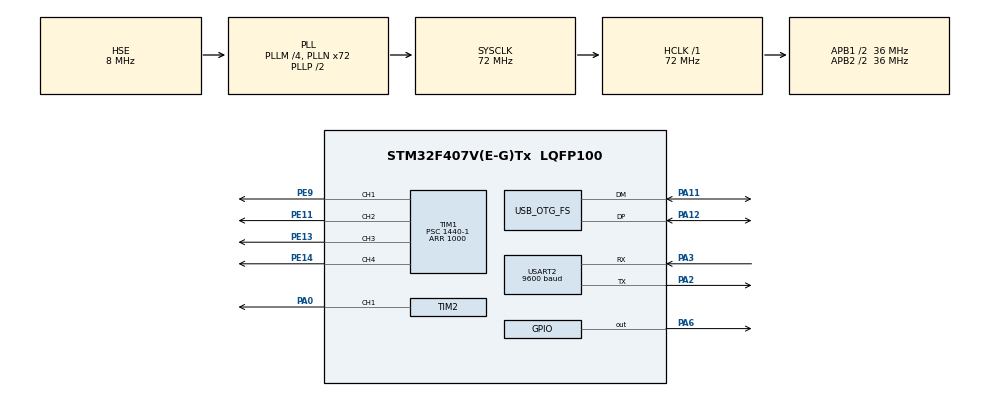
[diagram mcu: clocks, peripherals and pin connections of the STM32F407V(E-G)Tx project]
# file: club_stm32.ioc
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Mcu.Family=STM32F4
Mcu.Name=STM32F407V(E-G)Tx
Mcu.Package=LQFP100
NVIC.OTG_FS_IRQn=true\:0\:0\:false\:false\:true\:false\:true\:true
NVIC.PriorityGroup=NVIC_PRIORITYGROUP_4
NVIC.USART2_IRQn=true\:0\:0\:false\:false\:true\:true\:true\:true
PA0-WKUP.Signal=S_TIM2_CH1_ETR
PA11.Mode=Device_Only
PA11.Signal=USB_OTG_FS_DM
PA12.Mode=Device_Only
PA12.Signal=USB_OTG_FS_DP
PA2.Mode=Asynchronous
PA2.Signal=USART2_TX
PA3.Mode=Asynchronous
PA3.Signal=USART2_RX
PA6.Signal=GPIO_Output
PE11.Signal=S_TIM1_CH2
PE13.Signal=S_TIM1_CH3
PE14.Signal=S_TIM1_CH4
PE9.Signal=S_TIM1_CH1
PH0-OSC_IN.Mode=HSE-External-Oscillator
PH0-OSC_IN.Signal=RCC_OSC_IN
PH1-OSC_OUT.Mode=HSE-External-Oscillator
PH1-OSC_OUT.Signal=RCC_OSC_OUT
ProjectManager.HeapSize=0x200
ProjectManager.StackSize=0x400
ProjectManager.TargetToolchain=STM32CubeIDE
RCC.48MHZClocksFreq_Value=48000000
RCC.AHBFreq_Value=72000000
RCC.APB1CLKDivider=RCC_HCLK_DIV2
RCC.APB1Freq_Value=36000000
RCC.APB1TimFreq_Value=72000000
RCC.APB2CLKDivider=RCC_HCLK_DIV2
RCC.APB2Freq_Value=36000000
RCC.APB2TimFreq_Value=72000000
RCC.CortexFreq_Value=72000000
RCC.HCLKFreq_Value=72000000
RCC.HSE_VALUE=8000000
RCC.HSI_VALUE=16000000
RCC.LSE_VALUE=32768
RCC.PLLM=4
RCC.PLLN=72
RCC.PLLQ=3
RCC.SYSCLKFreq_VALUE=72000000
RCC.SYSCLKSource=RCC_SYSCLKSOURCE_PLLCLK
RCC.VCOOutputFreq_Value=144000000
SH.S_TIM1_CH1.0=TIM1_CH1,PWM Generation1 CH1
SH.S_TIM1_CH2.0=TIM1_CH2,PWM Generation2 CH2
SH.S_TIM1_CH3.0=TIM1_CH3,PWM Generation3 CH3
SH.S_TIM1_CH4.0=TIM1_CH4,PWM Generation4 CH4
SH.S_TIM2_CH1_ETR.0=TIM2_CH1,PWM Generation1 CH1
TIM1.Channel-PWM\ Generation1\ CH1=TIM_CHANNEL_1
TIM1.Channel-PWM\ Generation2\ CH2=TIM_CHANNEL_2
TIM1.Channel-PWM\ Generation3\ CH3=TIM_CHANNEL_3
TIM1.Channel-PWM\ Generation4\ CH4=TIM_CHANNEL_4
TIM1.Period=1000
TIM1.Prescaler=1440-1
TIM2.Channel-PWM\ Generation1\ CH1=TIM_CHANNEL_1
TIM2.Period=1000
TIM2.Prescaler=1440
USART2.BaudRate=9600
USART2.VirtualMode=VM_ASYNC
USB_DEVICE.CLASS_NAME_FS=CDC
USB_DEVICE.VirtualMode-CDC_FS=Cdc
USB_DEVICE.VirtualModeFS=Cdc_FS
USB_OTG_FS.VirtualMode=Device_Only
VP_TIM1_VS_ClockSourceINT.Mode=Internal
VP_TIM2_VS_ClockSourceINT.Mode=Internal
VP_USB_DEVICE_VS_USB_DEVICE_CDC_FS.Mode=CDC_FS
board=custom

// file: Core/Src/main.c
/* USER CODE BEGIN Header */
/**
  ******************************************************************************
  * @file           : main.c
  * @brief          : Main program body
  ******************************************************************************
  * @attention
  *
  * Copyright (c) 2024 STMicroelectronics.
  * All rights reserved.
  *
  * This software is licensed under terms that can be found in the LICENSE file
  * in the root directory of this software component.
  * If no LICENSE file comes with this software, it is provided AS-IS.
  *
  ******************************************************************************
  */
/* USER CODE END Header */
#include "main.h"
#include "usb_device.h"
#include "usbd_cdc_if.h"
#include <stdio.h>
#include <stdint.h>
#include <stdlib.h>

/* USER CODE BEGIN Includes */
#define RX_BUFFER_SIZE 5
uint8_t rxBuffer[RX_BUFFER_SIZE];
uint8_t rxIndex = 0;
/* USER CODE END Includes */

TIM_HandleTypeDef htim1;
TIM_HandleTypeDef htim2;

UART_HandleTypeDef huart2;

void SystemClock_Config(void);
static void MX_GPIO_Init(void);
static void MX_TIM1_Init(void);
static void MX_USART2_UART_Init(void);
static void MX_TIM2_Init(void);

int main(void)
{

  /* MCU Configuration--------------------------------------------------------*/

  /* Reset of all peripherals, Initializes the Flash interface and the Systick. */
  HAL_Init();

  /* Configure the system clock */
  SystemClock_Config();

  /* Initialize all configured peripherals */
  MX_GPIO_Init();
  MX_TIM1_Init();
  MX_TIM2_Init();
  MX_USB_DEVICE_Init();
  MX_USART2_UART_Init();
  HAL_TIM_PWM_Start(&htim1, TIM_CHANNEL_1);
  HAL_TIM_PWM_Start(&htim1, TIM_CHANNEL_2);
  HAL_TIM_PWM_Start(&htim1, TIM_CHANNEL_3);
  HAL_TIM_PWM_Start(&htim1, TIM_CHANNEL_4);
  HAL_TIM_PWM_Start(&htim2, TIM_CHANNEL_1);
  HAL_UART_Receive_IT(&huart2, &rxBuffer[rxIndex], 1);
  /* USER CODE BEGIN 2 */
//  HAL_UART_Receive_IT(&huart1, &rxBuffer[rxIndex], 1);

  /* USER CODE END 2 */

  /* Infinite loop */
    while (1)
    {

    }
}

void SystemClock_Config(void)
{
  RCC_OscInitTypeDef RCC_OscInitStruct = {0};
  RCC_ClkInitTypeDef RCC_ClkInitStruct = {0};

  /** Configure the main internal regulator output voltage
  */
  __HAL_RCC_PWR_CLK_ENABLE();
  __HAL_PWR_VOLTAGESCALING_CONFIG(PWR_REGULATOR_VOLTAGE_SCALE1);

  /** Initializes the RCC Oscillators according to the specified parameters
  * in the RCC_OscInitTypeDef structure.
  */
  RCC_OscInitStruct.OscillatorType = RCC_OSCILLATORTYPE_HSE;
  RCC_OscInitStruct.HSEState = RCC_HSE_ON;
  RCC_OscInitStruct.PLL.PLLState = RCC_PLL_ON;
  RCC_OscInitStruct.PLL.PLLSource = RCC_PLLSOURCE_HSE;
  RCC_OscInitStruct.PLL.PLLM = 4;
  RCC_OscInitStruct.PLL.PLLN = 72;
  RCC_OscInitStruct.PLL.PLLP = RCC_PLLP_DIV2;
  RCC_OscInitStruct.PLL.PLLQ = 3;
  if (HAL_RCC_OscConfig(&RCC_OscInitStruct) != HAL_OK)
  {
    Error_Handler();
  }

  /** Initializes the CPU, AHB and APB buses clocks
  */
  RCC_ClkInitStruct.ClockType = RCC_CLOCKTYPE_HCLK|RCC_CLOCKTYPE_SYSCLK
                              |RCC_CLOCKTYPE_PCLK1|RCC_CLOCKTYPE_PCLK2;
  RCC_ClkInitStruct.SYSCLKSource = RCC_SYSCLKSOURCE_PLLCLK;
  RCC_ClkInitStruct.AHBCLKDivider = RCC_SYSCLK_DIV1;
  RCC_ClkInitStruct.APB1CLKDivider = RCC_HCLK_DIV2;
  RCC_ClkInitStruct.APB2CLKDivider = RCC_HCLK_DIV2;

  if (HAL_RCC_ClockConfig(&RCC_ClkInitStruct, FLASH_LATENCY_2) != HAL_OK)
  {
    Error_Handler();
  }
}

static void MX_TIM1_Init(void)
{

  TIM_ClockConfigTypeDef sClockSourceConfig = {0};
  TIM_MasterConfigTypeDef sMasterConfig = {0};
  TIM_OC_InitTypeDef sConfigOC = {0};
  TIM_BreakDeadTimeConfigTypeDef sBreakDeadTimeConfig = {0};

  htim1.Instance = TIM1;
  htim1.Init.Prescaler = 1440-1;
  htim1.Init.CounterMode = TIM_COUNTERMODE_UP;
  htim1.Init.Period = 1000;
  htim1.Init.ClockDivision = TIM_CLOCKDIVISION_DIV1;
  htim1.Init.RepetitionCounter = 0;
  htim1.Init.AutoReloadPreload = TIM_AUTORELOAD_PRELOAD_DISABLE;
  if (HAL_TIM_Base_Init(&htim1) != HAL_OK)
  {
    Error_Handler();
  }
  sClockSourceConfig.ClockSource = TIM_CLOCKSOURCE_INTERNAL;
  if (HAL_TIM_ConfigClockSource(&htim1, &sClockSourceConfig) != HAL_OK)
  {
    Error_Handler();
  }
  if (HAL_TIM_PWM_Init(&htim1) != HAL_OK)
  {
    Error_Handler();
  }
  sMasterConfig.MasterOutputTrigger = TIM_TRGO_RESET;
  sMasterConfig.MasterSlaveMode = TIM_MASTERSLAVEMODE_DISABLE;
  if (HAL_TIMEx_MasterConfigSynchronization(&htim1, &sMasterConfig) != HAL_OK)
  {
    Error_Handler();
  }
  sConfigOC.OCMode = TIM_OCMODE_PWM1;
  sConfigOC.Pulse = 0;
  sConfigOC.OCPolarity = TIM_OCPOLARITY_HIGH;
  sConfigOC.OCNPolarity = TIM_OCNPOLARITY_HIGH;
  sConfigOC.OCFastMode = TIM_OCFAST_DISABLE;
  sConfigOC.OCIdleState = TIM_OCIDLESTATE_RESET;
  sConfigOC.OCNIdleState = TIM_OCNIDLESTATE_RESET;
  if (HAL_TIM_PWM_ConfigChannel(&htim1, &sConfigOC, TIM_CHANNEL_1) != HAL_OK)
  {
    Error_Handler();
  }
  if (HAL_TIM_PWM_ConfigChannel(&htim1, &sConfigOC, TIM_CHANNEL_2) != HAL_OK)
  {
    Error_Handler();
  }
  if (HAL_TIM_PWM_ConfigChannel(&htim1, &sConfigOC, TIM_CHANNEL_3) != HAL_OK)
  {
    Error_Handler();
  }
  if (HAL_TIM_PWM_ConfigChannel(&htim1, &sConfigOC, TIM_CHANNEL_4) != HAL_OK)
  {
    Error_Handler();
  }
  sBreakDeadTimeConfig.OffStateRunMode = TIM_OSSR_DISABLE;
  sBreakDeadTimeConfig.OffStateIDLEMode = TIM_OSSI_DISABLE;
  sBreakDeadTimeConfig.LockLevel = TIM_LOCKLEVEL_OFF;
  sBreakDeadTimeConfig.DeadTime = 0;
  sBreakDeadTimeConfig.BreakState = TIM_BREAK_DISABLE;
  sBreakDeadTimeConfig.BreakPolarity = TIM_BREAKPOLARITY_HIGH;
  sBreakDeadTimeConfig.AutomaticOutput = TIM_AUTOMATICOUTPUT_DISABLE;
  if (HAL_TIMEx_ConfigBreakDeadTime(&htim1, &sBreakDeadTimeConfig) != HAL_OK)
  {
    Error_Handler();
  }
  HAL_TIM_MspPostInit(&htim1);

}

static void MX_TIM2_Init(void)
{

  TIM_ClockConfigTypeDef sClockSourceConfig = {0};
  TIM_MasterConfigTypeDef sMasterConfig = {0};
  TIM_OC_InitTypeDef sConfigOC = {0};

  htim2.Instance = TIM2;
  htim2.Init.Prescaler = 1440;
  htim2.Init.CounterMode = TIM_COUNTERMODE_UP;
  htim2.Init.Period = 1000;
  htim2.Init.ClockDivision = TIM_CLOCKDIVISION_DIV1;
  htim2.Init.AutoReloadPreload = TIM_AUTORELOAD_PRELOAD_DISABLE;
  if (HAL_TIM_Base_Init(&htim2) != HAL_OK)
  {
    Error_Handler();
  }
  sClockSourceConfig.ClockSource = TIM_CLOCKSOURCE_INTERNAL;
  if (HAL_TIM_ConfigClockSource(&htim2, &sClockSourceConfig) != HAL_OK)
  {
    Error_Handler();
  }
  if (HAL_TIM_PWM_Init(&htim2) != HAL_OK)
  {
    Error_Handler();
  }
  sMasterConfig.MasterOutputTrigger = TIM_TRGO_RESET;
  sMasterConfig.MasterSlaveMode = TIM_MASTERSLAVEMODE_DISABLE;
  if (HAL_TIMEx_MasterConfigSynchronization(&htim2, &sMasterConfig) != HAL_OK)
  {
    Error_Handler();
  }
  sConfigOC.OCMode = TIM_OCMODE_PWM1;
  sConfigOC.Pulse = 0;
  sConfigOC.OCPolarity = TIM_OCPOLARITY_HIGH;
  sConfigOC.OCFastMode = TIM_OCFAST_DISABLE;
  if (HAL_TIM_PWM_ConfigChannel(&htim2, &sConfigOC, TIM_CHANNEL_1) != HAL_OK)
  {
    Error_Handler();
  }
  HAL_TIM_MspPostInit(&htim2);

}

static void MX_USART2_UART_Init(void)
{

  huart2.Instance = USART2;
  huart2.Init.BaudRate = 9600;
  huart2.Init.WordLength = UART_WORDLENGTH_8B;
  huart2.Init.StopBits = UART_STOPBITS_1;
  huart2.Init.Parity = UART_PARITY_NONE;
  huart2.Init.Mode = UART_MODE_TX_RX;
  huart2.Init.HwFlowCtl = UART_HWCONTROL_NONE;
  huart2.Init.OverSampling = UART_OVERSAMPLING_16;
  if (HAL_UART_Init(&huart2) != HAL_OK)
  {
    Error_Handler();
  }

}

static void MX_GPIO_Init(void)
{
  GPIO_InitTypeDef GPIO_InitStruct = {0};

  /* GPIO Ports Clock Enable */
  __HAL_RCC_GPIOH_CLK_ENABLE();
  __HAL_RCC_GPIOA_CLK_ENABLE();
  __HAL_RCC_GPIOE_CLK_ENABLE();

  /*Configure GPIO pin Output Level */
  HAL_GPIO_WritePin(GPIOA, GPIO_PIN_6, GPIO_PIN_RESET);

  /*Configure GPIO pin : PA6 */
  GPIO_InitStruct.Pin = GPIO_PIN_6;
  GPIO_InitStruct.Mode = GPIO_MODE_OUTPUT_PP;
  GPIO_InitStruct.Pull = GPIO_NOPULL;
  GPIO_InitStruct.Speed = GPIO_SPEED_FREQ_LOW;
  HAL_GPIO_Init(GPIOA, &GPIO_InitStruct);

}

void Error_Handler(void)
{
  __disable_irq();
  while (1)
  {
  }
}

int get_angle(uint8_t *rxBuffer) {
    // Check if rxBuffer is valid
    if (rxBuffer == NULL) {
        printf("Invalid input\n");
        return -1;
    }

    // Check if the starting characters are "s6"
    if (rxBuffer[0] == 's') {
        printf("The input starts with 's6'.\n");
    } else {
        printf("The input does not start with 's6'.\n");
        return -1;  // Return an error or handle as needed
    }

    // Create a temporary string buffer to hold the last 3 characters as a string
    char angleStr[4] = {0};  // 3 characters for angle + 1 null terminator
    angleStr[0] = rxBuffer[2];
    angleStr[1] = rxBuffer[3];
    angleStr[2] = rxBuffer[4];

    // Convert the extracted characters to an integer
    int angle = atoi(angleStr);

    return angle;
}

void HAL_UART_RxCpltCallback(UART_HandleTypeDef *huart)
{
    if (huart->Instance == USART2)
    {
        // Increment the index for each received byte
        rxIndex++;

        // Check if we've received the full 5-byte message
        if (rxIndex >= RX_BUFFER_SIZE)
        {
            // Process the full message without echoing it back to the PC
            if (rxBuffer[0] == 's' && rxBuffer[1] == '6') {
                 int raw_angle = get_angle(rxBuffer);

                 if (raw_angle >= 0) {  // Ensure get_angle did not return an error
                     float angle = (raw_angle / 1.8f) + 25.0f;
                     __HAL_TIM_SET_COMPARE(&htim1, TIM_CHANNEL_1, (int)angle);
                 }
             }
            else if (rxBuffer[0] == 's' && rxBuffer[1] == '5') {
                 int raw_angle = get_angle(rxBuffer);

                 if (raw_angle >= 0) {  // Ensure get_angle did not return an error
                     float angle = (raw_angle / 1.8f) + 25.0f;
                     __HAL_TIM_SET_COMPARE(&htim1, TIM_CHANNEL_2, (int)angle);
                 }
             }
            else if (rxBuffer[0] == 's' && rxBuffer[1] == '4') {
                 int raw_angle = get_angle(rxBuffer);

                 if (raw_angle >= 0) {  // Ensure get_angle did not return an error
                     float angle = (raw_angle / 1.8f) + 25.0f;
                     __HAL_TIM_SET_COMPARE(&htim1, TIM_CHANNEL_3, (int)angle);
                 }
            }
            else if (rxBuffer[0] == 's' && rxBuffer[1] == '3') {
                 int raw_angle = get_angle(rxBuffer);

                 if (raw_angle >= 0) {  // Ensure get_angle did not return an error
                     float angle = (raw_angle / 1.8f) + 25.0f;
                     __HAL_TIM_SET_COMPARE(&htim1, TIM_CHANNEL_4, (int)angle);
                 }
            }
            else if (rxBuffer[0] == 's' && rxBuffer[1] == '2') {
                 int raw_angle = get_angle(rxBuffer);

                 if (raw_angle >= 0) {  // Ensure get_angle did not return an error
                     float angle = (raw_angle / 1.8f) + 25.0f;
                     __HAL_TIM_SET_COMPARE(&htim2, TIM_CHANNEL_1, (int)angle);
                 }
            }
            // Send the received message to the CDC (Virtual COM Port)
            CDC_Transmit_FS(rxBuffer, RX_BUFFER_SIZE);

            rxIndex = 0;  // Reset the index to start a new message
        }

        // Re-enable UART receive interrupt to continue receiving
        HAL_UART_Receive_IT(&huart2, &rxBuffer[rxIndex], 1);
    }
}
